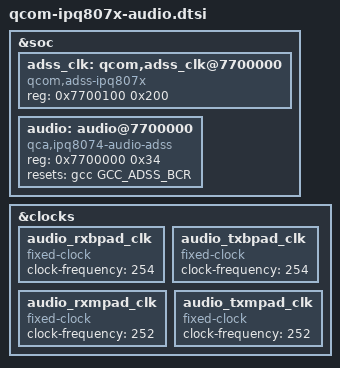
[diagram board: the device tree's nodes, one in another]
/*
 * Copyright (c) 2017, The Linux Foundation. All rights reserved.
 *
 * Permission to use, copy, modify, and/or distribute this software for any
 * purpose with or without fee is hereby granted, provided that the above
 * copyright notice and this permission notice appear in all copies.
 *
 * THE SOFTWARE IS PROVIDED "AS IS" AND THE AUTHOR DISCLAIMS ALL WARRANTIES
 * WITH REGARD TO THIS SOFTWARE INCLUDING ALL IMPLIED WARRANTIES OF
 * MERCHANTABILITY AND FITNESS. IN NO EVENT SHALL THE AUTHOR BE LIABLE FOR
 * ANY SPECIAL, DIRECT, INDIRECT, OR CONSEQUENTIAL DAMAGES OR ANY DAMAGES
 * WHATSOEVER RESULTING FROM LOSS OF USE, DATA OR PROFITS, WHETHER IN AN
 * ACTION OF CONTRACT, NEGLIGENCE OR OTHER TORTIOUS ACTION, ARISING OUT OF
 * OR IN CONNECTION WITH THE USE OR PERFORMANCE OF THIS SOFTWARE.
 */
#include <dt-bindings/sound/ipq8074-audio.h>
#include <dt-bindings/clock/qca,adss-ipq807x.h>


&soc {
	adss_clk: qcom,adss_clk@7700000 {
		compatible = "qcom,adss-ipq807x";
		reg = <0x7700100 0x200>;
		#clock-cells = <0x1>;
	};

	audio: audio@7700000 {
		compatible = "qca,ipq8074-audio-adss";
		reg = <0x7700000 0x34>;
		resets = <&gcc GCC_ADSS_BCR>;
		reset-names = "blk_rst";
	};
};

&clocks {
	audio_rxbpad_clk {
		compatible = "fixed-clock";
		clock-frequency = <254>;
		#clock-cells = <0>;
	};

	audio_txbpad_clk {
		compatible = "fixed-clock";
		clock-frequency = <254>;
		#clock-cells = <0>;
	};

	audio_rxmpad_clk {
		compatible = "fixed-clock";
		clock-frequency = <252>;
		#clock-cells = <0>;
	};

	audio_txmpad_clk {
		compatible = "fixed-clock";
		clock-frequency = <252>;
		#clock-cells = <0>;
	};
};
